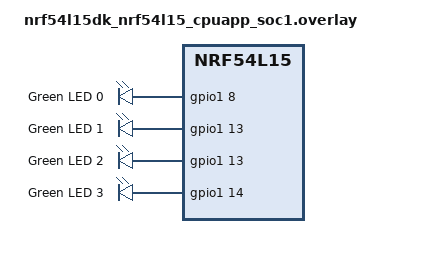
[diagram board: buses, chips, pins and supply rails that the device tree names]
/*
 * Copyright (c) 2023 Nordic Semiconductor ASA
 *
 * SPDX-License-Identifier: LicenseRef-Nordic-5-Clause
 */

/* Temporary fix for nRF54L15 LEDs, due to LED0 be always on.
 * This sample requires LEDs redifinition becuase it uses LED0, LED3, LED4 and nRF54L15 PDK has
 * only three functional LEDs. The LED 0 is replaced by LED 1.
 *
 * TODO: It shall be removed for future nRF54L15 batches.
 */
/ {
	/delete-node/ leds;

	leds {
		compatible = "gpio-leds";
		led0: led_0 {
			gpios = <&gpio1 8 GPIO_ACTIVE_HIGH>;
			label = "Green LED 0";
		};
		led1: led_1 {
			gpios = <&gpio1 13 GPIO_ACTIVE_HIGH>;
			label = "Green LED 1";
		};
		led2: led_2 {
			gpios = <&gpio1 13 GPIO_ACTIVE_HIGH>;
			label = "Green LED 2";
		};
		led3: led_3 {
			gpios = <&gpio1 14 GPIO_ACTIVE_HIGH>;
			label = "Green LED 3";
		};
	};
};
